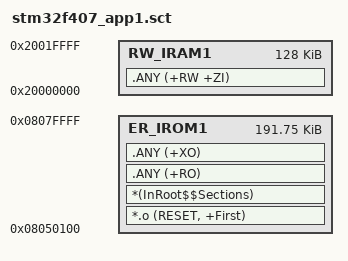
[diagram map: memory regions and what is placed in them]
; *************************************************************
; *** Scatter-Loading Description File for APP1 ***
; *************************************************************

LR_IROM1 0x08050100 0x0002FF00  {    ; APP1: start=0x08050100, size=192KB-256B
  ER_IROM1 0x08050100 0x0002FF00  {
   *.o (RESET, +First)
   *(InRoot$$Sections)
   .ANY (+RO)
   .ANY (+XO)
  }
  RW_IRAM1 0x20000000 0x00020000  {
   .ANY (+RW +ZI)
  }
}
